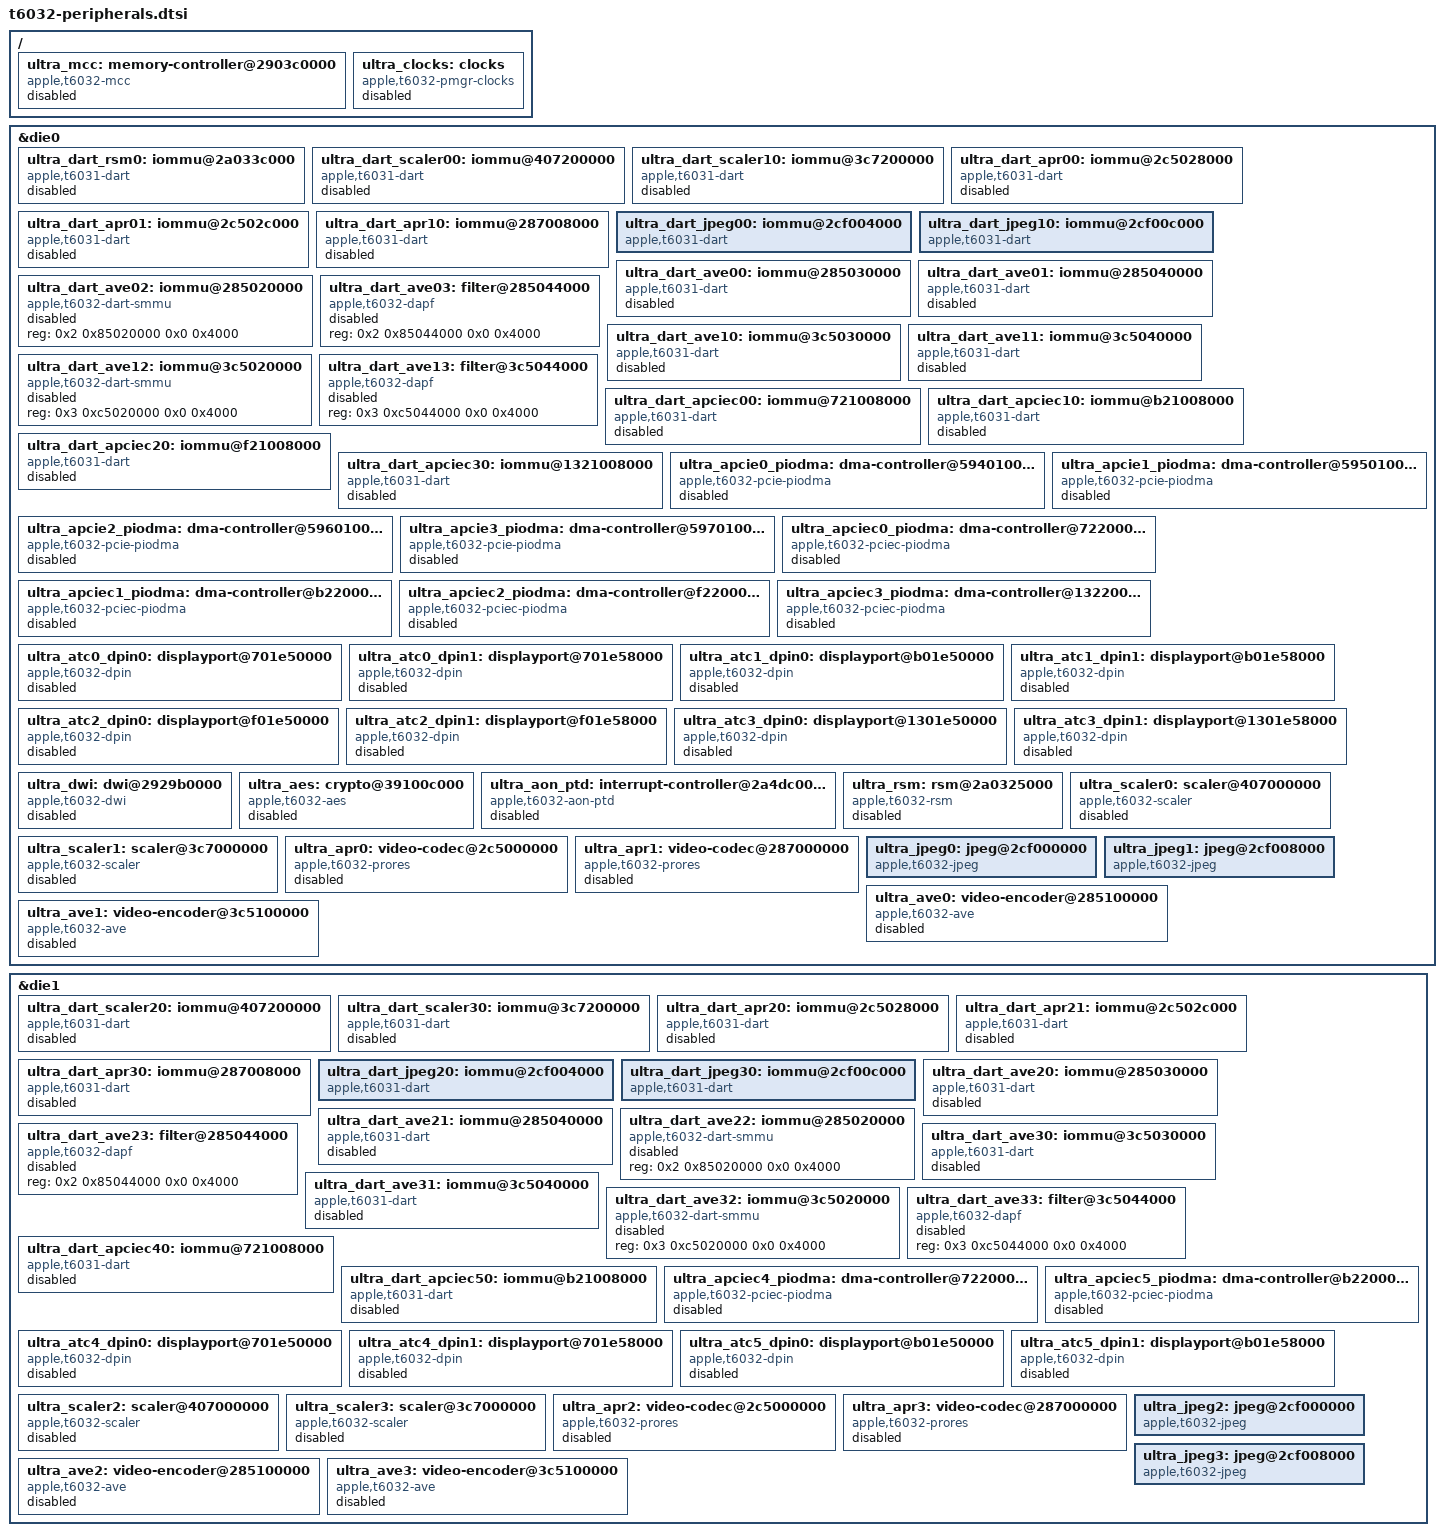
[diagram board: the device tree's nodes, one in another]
// SPDX-License-Identifier: GPL-2.0+ OR MIT
/* Unclaimed resources of both T6032 dies. */

&die0 {
	ultra_dart_rsm0: iommu@2a033c000 {
		compatible = "apple,t6031-dart", "apple,t8110-dart";
		reg = <0x2 0xa033c000 0x0 0x4000>;
		interrupt-parent = <&aic>;
		interrupts = <AIC_IRQ 0 559 IRQ_TYPE_LEVEL_HIGH>;
		#iommu-cells = <1>;
		status = "disabled";
	};

	ultra_dart_scaler00: iommu@407200000 {
		compatible = "apple,t6031-dart", "apple,t8110-dart";
		reg = <0x4 0x07200000 0x0 0x4000>;
		interrupt-parent = <&aic>;
		interrupts = <AIC_IRQ 0 1292 IRQ_TYPE_LEVEL_HIGH>;
		#iommu-cells = <1>;
		status = "disabled";
	};

	ultra_dart_scaler10: iommu@3c7200000 {
		compatible = "apple,t6031-dart", "apple,t8110-dart";
		reg = <0x3 0xc7200000 0x0 0x4000>;
		interrupt-parent = <&aic>;
		interrupts = <AIC_IRQ 0 1298 IRQ_TYPE_LEVEL_HIGH>;
		#iommu-cells = <1>;
		status = "disabled";
	};

	ultra_dart_apr00: iommu@2c5028000 {
		compatible = "apple,t6031-dart", "apple,t8110-dart";
		reg = <0x2 0xc5028000 0x0 0x4000>;
		interrupt-parent = <&aic>;
		interrupts = <AIC_IRQ 0 1737 IRQ_TYPE_LEVEL_HIGH>;
		#iommu-cells = <1>;
		status = "disabled";
	};

	ultra_dart_apr01: iommu@2c502c000 {
		compatible = "apple,t6031-dart", "apple,t8110-dart";
		reg = <0x2 0xc502c000 0x0 0x4000>;
		interrupt-parent = <&aic>;
		interrupts = <AIC_IRQ 0 1737 IRQ_TYPE_LEVEL_HIGH>;
		#iommu-cells = <1>;
		status = "disabled";
	};

	ultra_dart_apr10: iommu@287008000 {
		compatible = "apple,t6031-dart", "apple,t8110-dart";
		reg = <0x2 0x87008000 0x0 0x4000>;
		interrupt-parent = <&aic>;
		interrupts = <AIC_IRQ 0 1782 IRQ_TYPE_LEVEL_HIGH>;
		#iommu-cells = <1>;
		status = "disabled";
	};

	ultra_dart_jpeg00: iommu@2cf004000 {
		compatible = "apple,t6031-dart", "apple,t8110-dart";
		reg = <0x2 0xcf004000 0x0 0x4000>;
		interrupt-parent = <&aic>;
		interrupts = <AIC_IRQ 0 1283 IRQ_TYPE_LEVEL_HIGH>;
		#iommu-cells = <1>;
		status = "okay";
	};

	ultra_dart_jpeg10: iommu@2cf00c000 {
		compatible = "apple,t6031-dart", "apple,t8110-dart";
		reg = <0x2 0xcf00c000 0x0 0x4000>;
		interrupt-parent = <&aic>;
		interrupts = <AIC_IRQ 0 1288 IRQ_TYPE_LEVEL_HIGH>;
		#iommu-cells = <1>;
		status = "okay";
	};

	ultra_dart_ave00: iommu@285030000 {
		compatible = "apple,t6031-dart", "apple,t8110-dart";
		reg = <0x2 0x85030000 0x0 0x4000>;
		interrupt-parent = <&aic>;
		interrupts = <AIC_IRQ 0 1204 IRQ_TYPE_LEVEL_HIGH>;
		#iommu-cells = <1>;
		status = "disabled";
	};

	ultra_dart_ave01: iommu@285040000 {
		compatible = "apple,t6031-dart", "apple,t8110-dart";
		reg = <0x2 0x85040000 0x0 0x4000>;
		interrupt-parent = <&aic>;
		interrupts = <AIC_IRQ 0 1204 IRQ_TYPE_LEVEL_HIGH>;
		#iommu-cells = <1>;
		status = "disabled";
	};

	ultra_dart_ave02: iommu@285020000 {
		compatible = "apple,t6032-dart-smmu", "apple,dart-smmu";
		reg = <0x2 0x85020000 0x0 0x4000>;
		status = "disabled";
	};

	ultra_dart_ave03: filter@285044000 {
		compatible = "apple,t6032-dapf", "apple,dapf";
		reg = <0x2 0x85044000 0x0 0x4000>;
		status = "disabled";
	};

	ultra_dart_ave10: iommu@3c5030000 {
		compatible = "apple,t6031-dart", "apple,t8110-dart";
		reg = <0x3 0xc5030000 0x0 0x4000>;
		interrupt-parent = <&aic>;
		interrupts = <AIC_IRQ 0 1216 IRQ_TYPE_LEVEL_HIGH>;
		#iommu-cells = <1>;
		status = "disabled";
	};

	ultra_dart_ave11: iommu@3c5040000 {
		compatible = "apple,t6031-dart", "apple,t8110-dart";
		reg = <0x3 0xc5040000 0x0 0x4000>;
		interrupt-parent = <&aic>;
		interrupts = <AIC_IRQ 0 1216 IRQ_TYPE_LEVEL_HIGH>;
		#iommu-cells = <1>;
		status = "disabled";
	};

	ultra_dart_ave12: iommu@3c5020000 {
		compatible = "apple,t6032-dart-smmu", "apple,dart-smmu";
		reg = <0x3 0xc5020000 0x0 0x4000>;
		status = "disabled";
	};

	ultra_dart_ave13: filter@3c5044000 {
		compatible = "apple,t6032-dapf", "apple,dapf";
		reg = <0x3 0xc5044000 0x0 0x4000>;
		status = "disabled";
	};

	ultra_dart_apciec00: iommu@721008000 {
		compatible = "apple,t6031-dart", "apple,t8110-dart";
		reg = <0x7 0x21008000 0x0 0x4000>;
		interrupt-parent = <&aic>;
		interrupts = <AIC_IRQ 0 1348 IRQ_TYPE_LEVEL_HIGH>;
		#iommu-cells = <1>;
		status = "disabled";
	};

	ultra_dart_apciec10: iommu@b21008000 {
		compatible = "apple,t6031-dart", "apple,t8110-dart";
		reg = <0xb 0x21008000 0x0 0x4000>;
		interrupt-parent = <&aic>;
		interrupts = <AIC_IRQ 0 1376 IRQ_TYPE_LEVEL_HIGH>;
		#iommu-cells = <1>;
		status = "disabled";
	};

	ultra_dart_apciec20: iommu@f21008000 {
		compatible = "apple,t6031-dart", "apple,t8110-dart";
		reg = <0xf 0x21008000 0x0 0x4000>;
		interrupt-parent = <&aic>;
		interrupts = <AIC_IRQ 0 1404 IRQ_TYPE_LEVEL_HIGH>;
		#iommu-cells = <1>;
		status = "disabled";
	};

	ultra_dart_apciec30: iommu@1321008000 {
		compatible = "apple,t6031-dart", "apple,t8110-dart";
		reg = <0x13 0x21008000 0x0 0x4000>;
		interrupt-parent = <&aic>;
		interrupts = <AIC_IRQ 0 1432 IRQ_TYPE_LEVEL_HIGH>;
		#iommu-cells = <1>;
		status = "disabled";
	};

	ultra_apcie0_piodma: dma-controller@594010000 {
		compatible = "apple,t6032-pcie-piodma", "apple,pcie-piodma";
		reg = <0x5 0x94010000 0x0 0x4000>,
		      <0x5 0x94014000 0x0 0x4000>,
		      <0x5 0x94018000 0x0 0x4000>;
		interrupt-parent = <&aic>;
		interrupts = <AIC_IRQ 0 1493 IRQ_TYPE_LEVEL_HIGH>;
		iommus = <&pcie0_dart_0 15>;
		status = "disabled";
	};

	ultra_apcie1_piodma: dma-controller@595010000 {
		compatible = "apple,t6032-pcie-piodma", "apple,pcie-piodma";
		reg = <0x5 0x95010000 0x0 0x4000>,
		      <0x5 0x95014000 0x0 0x4000>,
		      <0x5 0x95018000 0x0 0x4000>;
		interrupt-parent = <&aic>;
		interrupts = <AIC_IRQ 0 1502 IRQ_TYPE_LEVEL_HIGH>;
		iommus = <&pcie0_dart_1 15>;
		status = "disabled";
	};

	ultra_apcie2_piodma: dma-controller@596010000 {
		compatible = "apple,t6032-pcie-piodma", "apple,pcie-piodma";
		reg = <0x5 0x96010000 0x0 0x4000>,
		      <0x5 0x96014000 0x0 0x4000>,
		      <0x5 0x96018000 0x0 0x4000>;
		interrupt-parent = <&aic>;
		interrupts = <AIC_IRQ 0 1511 IRQ_TYPE_LEVEL_HIGH>;
		status = "disabled";
	};

	ultra_apcie3_piodma: dma-controller@597010000 {
		compatible = "apple,t6032-pcie-piodma", "apple,pcie-piodma";
		reg = <0x5 0x97010000 0x0 0x4000>,
		      <0x5 0x97014000 0x0 0x4000>,
		      <0x5 0x97018000 0x0 0x4000>;
		interrupt-parent = <&aic>;
		interrupts = <AIC_IRQ 0 1520 IRQ_TYPE_LEVEL_HIGH>;
		status = "disabled";
	};

	ultra_apciec0_piodma: dma-controller@722000000 {
		compatible = "apple,t6032-pciec-piodma", "apple,pciec-piodma";
		reg = <0x7 0x22000000 0x0 0x4000>,
		      <0x7 0x22004000 0x0 0x4000>,
		      <0x7 0x22008000 0x0 0x4000>,
		      <0x7 0x20008000 0x0 0x4000>;
		interrupt-parent = <&aic>;
		interrupts = <AIC_IRQ 0 1349 IRQ_TYPE_LEVEL_HIGH>;
		iommus = <&ultra_dart_apciec00 15>;
		status = "disabled";
	};

	ultra_apciec1_piodma: dma-controller@b22000000 {
		compatible = "apple,t6032-pciec-piodma", "apple,pciec-piodma";
		reg = <0xb 0x22000000 0x0 0x4000>,
		      <0xb 0x22004000 0x0 0x4000>,
		      <0xb 0x22008000 0x0 0x4000>,
		      <0xb 0x20008000 0x0 0x4000>;
		interrupt-parent = <&aic>;
		interrupts = <AIC_IRQ 0 1377 IRQ_TYPE_LEVEL_HIGH>;
		iommus = <&ultra_dart_apciec10 15>;
		status = "disabled";
	};

	ultra_apciec2_piodma: dma-controller@f22000000 {
		compatible = "apple,t6032-pciec-piodma", "apple,pciec-piodma";
		reg = <0xf 0x22000000 0x0 0x4000>,
		      <0xf 0x22004000 0x0 0x4000>,
		      <0xf 0x22008000 0x0 0x4000>,
		      <0xf 0x20008000 0x0 0x4000>;
		interrupt-parent = <&aic>;
		interrupts = <AIC_IRQ 0 1405 IRQ_TYPE_LEVEL_HIGH>;
		iommus = <&ultra_dart_apciec20 15>;
		status = "disabled";
	};

	ultra_apciec3_piodma: dma-controller@1322000000 {
		compatible = "apple,t6032-pciec-piodma", "apple,pciec-piodma";
		reg = <0x13 0x22000000 0x0 0x4000>,
		      <0x13 0x22004000 0x0 0x4000>,
		      <0x13 0x22008000 0x0 0x4000>,
		      <0x13 0x20008000 0x0 0x4000>;
		interrupt-parent = <&aic>;
		interrupts = <AIC_IRQ 0 1433 IRQ_TYPE_LEVEL_HIGH>;
		iommus = <&ultra_dart_apciec30 15>;
		status = "disabled";
	};

	ultra_atc0_dpin0: displayport@701e50000 {
		compatible = "apple,t6032-dpin", "apple,dpin";
		reg = <0x7 0x01e50000 0x0 0x4000>;
		interrupt-parent = <&aic>;
		interrupts = <AIC_IRQ 0 1564 IRQ_TYPE_LEVEL_HIGH>;
		status = "disabled";
	};

	ultra_atc0_dpin1: displayport@701e58000 {
		compatible = "apple,t6032-dpin", "apple,dpin";
		reg = <0x7 0x01e58000 0x0 0x4000>;
		interrupt-parent = <&aic>;
		interrupts = <AIC_IRQ 0 1565 IRQ_TYPE_LEVEL_HIGH>;
		status = "disabled";
	};

	ultra_atc1_dpin0: displayport@b01e50000 {
		compatible = "apple,t6032-dpin", "apple,dpin";
		reg = <0xb 0x01e50000 0x0 0x4000>;
		interrupt-parent = <&aic>;
		interrupts = <AIC_IRQ 0 1612 IRQ_TYPE_LEVEL_HIGH>;
		status = "disabled";
	};

	ultra_atc1_dpin1: displayport@b01e58000 {
		compatible = "apple,t6032-dpin", "apple,dpin";
		reg = <0xb 0x01e58000 0x0 0x4000>;
		interrupt-parent = <&aic>;
		interrupts = <AIC_IRQ 0 1613 IRQ_TYPE_LEVEL_HIGH>;
		status = "disabled";
	};

	ultra_atc2_dpin0: displayport@f01e50000 {
		compatible = "apple,t6032-dpin", "apple,dpin";
		reg = <0xf 0x01e50000 0x0 0x4000>;
		interrupt-parent = <&aic>;
		interrupts = <AIC_IRQ 0 1660 IRQ_TYPE_LEVEL_HIGH>;
		status = "disabled";
	};

	ultra_atc2_dpin1: displayport@f01e58000 {
		compatible = "apple,t6032-dpin", "apple,dpin";
		reg = <0xf 0x01e58000 0x0 0x4000>;
		interrupt-parent = <&aic>;
		interrupts = <AIC_IRQ 0 1661 IRQ_TYPE_LEVEL_HIGH>;
		status = "disabled";
	};

	ultra_atc3_dpin0: displayport@1301e50000 {
		compatible = "apple,t6032-dpin", "apple,dpin";
		reg = <0x13 0x01e50000 0x0 0x4000>;
		interrupt-parent = <&aic>;
		interrupts = <AIC_IRQ 0 1708 IRQ_TYPE_LEVEL_HIGH>;
		status = "disabled";
	};

	ultra_atc3_dpin1: displayport@1301e58000 {
		compatible = "apple,t6032-dpin", "apple,dpin";
		reg = <0x13 0x01e58000 0x0 0x4000>;
		interrupt-parent = <&aic>;
		interrupts = <AIC_IRQ 0 1709 IRQ_TYPE_LEVEL_HIGH>;
		status = "disabled";
	};

	ultra_dwi: dwi@2929b0000 {
		compatible = "apple,t6032-dwi", "apple,dwi";
		reg = <0x2 0x929b0000 0x0 0x4000>;
		interrupt-parent = <&aic>;
		interrupts = <AIC_IRQ 0 22 IRQ_TYPE_LEVEL_HIGH>;
		power-domains = <&ps_dwi>;
		status = "disabled";
	};

	ultra_aes: crypto@39100c000 {
		compatible = "apple,t6032-aes", "apple,aes";
		reg = <0x3 0x9100c000 0x0 0x4000>,
		      <0x2 0xa02a0000 0x0 0x8000>;
		interrupt-parent = <&aic>;
		interrupts = <AIC_IRQ 0 1324 IRQ_TYPE_LEVEL_HIGH>;
		power-domains = <&ps_aes>;
		iommus = <&sio_dart 1>;
		status = "disabled";
	};

	ultra_aon_ptd: interrupt-controller@2a4dc0000 {
		compatible = "apple,t6032-aon-ptd", "apple,aon-ptd";
		reg = <0x2 0xa4dc0000 0x0 0x4000>,
		      <0x2 0xa4dd0000 0x0 0x4000>,
		      <0x2 0xa4dd8000 0x0 0x4000>,
		      <0x2 0xa4de0000 0x0 0x4000>;
		interrupt-parent = <&aic>;
		interrupts = <AIC_IRQ 0 920 IRQ_TYPE_LEVEL_HIGH>,
		             <AIC_IRQ 0 921 IRQ_TYPE_LEVEL_HIGH>,
		             <AIC_IRQ 0 922 IRQ_TYPE_LEVEL_HIGH>,
		             <AIC_IRQ 0 923 IRQ_TYPE_LEVEL_HIGH>,
		             <AIC_IRQ 0 924 IRQ_TYPE_LEVEL_HIGH>,
		             <AIC_IRQ 0 925 IRQ_TYPE_LEVEL_HIGH>,
		             <AIC_IRQ 0 926 IRQ_TYPE_LEVEL_HIGH>,
		             <AIC_IRQ 0 927 IRQ_TYPE_LEVEL_HIGH>,
		             <AIC_IRQ 0 928 IRQ_TYPE_LEVEL_HIGH>,
		             <AIC_IRQ 0 929 IRQ_TYPE_LEVEL_HIGH>,
		             <AIC_IRQ 0 930 IRQ_TYPE_LEVEL_HIGH>,
		             <AIC_IRQ 0 931 IRQ_TYPE_LEVEL_HIGH>,
		             <AIC_IRQ 0 932 IRQ_TYPE_LEVEL_HIGH>,
		             <AIC_IRQ 0 933 IRQ_TYPE_LEVEL_HIGH>,
		             <AIC_IRQ 0 934 IRQ_TYPE_LEVEL_HIGH>,
		             <AIC_IRQ 0 935 IRQ_TYPE_LEVEL_HIGH>,
		             <AIC_IRQ 0 936 IRQ_TYPE_LEVEL_HIGH>,
		             <AIC_IRQ 0 937 IRQ_TYPE_LEVEL_HIGH>,
		             <AIC_IRQ 0 938 IRQ_TYPE_LEVEL_HIGH>,
		             <AIC_IRQ 0 939 IRQ_TYPE_LEVEL_HIGH>,
		             <AIC_IRQ 0 940 IRQ_TYPE_LEVEL_HIGH>,
		             <AIC_IRQ 0 941 IRQ_TYPE_LEVEL_HIGH>,
		             <AIC_IRQ 0 942 IRQ_TYPE_LEVEL_HIGH>,
		             <AIC_IRQ 0 943 IRQ_TYPE_LEVEL_HIGH>,
		             <AIC_IRQ 0 944 IRQ_TYPE_LEVEL_HIGH>,
		             <AIC_IRQ 0 945 IRQ_TYPE_LEVEL_HIGH>,
		             <AIC_IRQ 0 946 IRQ_TYPE_LEVEL_HIGH>,
		             <AIC_IRQ 0 947 IRQ_TYPE_LEVEL_HIGH>,
		             <AIC_IRQ 0 948 IRQ_TYPE_LEVEL_HIGH>,
		             <AIC_IRQ 0 949 IRQ_TYPE_LEVEL_HIGH>,
		             <AIC_IRQ 0 950 IRQ_TYPE_LEVEL_HIGH>,
		             <AIC_IRQ 0 951 IRQ_TYPE_LEVEL_HIGH>;
		interrupt-controller;
		#interrupt-cells = <1>;
		#address-cells = <0>;
		status = "disabled";
	};

	ultra_rsm: rsm@2a0325000 {
		compatible = "apple,t6032-rsm", "apple,rsm";
		reg = <0x2 0xa0325000 0x0 0x4000>,
		      <0x2 0xa03c0000 0x0 0x4>;
		interrupt-parent = <&aic>;
		interrupts = <AIC_IRQ 0 556 IRQ_TYPE_LEVEL_HIGH>;
		power-domains = <&ps_debug_gated>;
		iommus = <&ultra_dart_rsm0 0>;
		status = "disabled";
	};

	ultra_scaler0: scaler@407000000 {
		compatible = "apple,t6032-scaler", "apple,scaler";
		reg = <0x4 0x07000000 0x0 0x30000>,
		      <0x4 0x07210000 0x0 0x4000>,
		      <0x4 0x07204000 0x0 0x4000>,
		      <0x4 0x06000000 0x0 0x8000>;
		interrupt-parent = <&aic>;
		interrupts = <AIC_IRQ 0 1291 IRQ_TYPE_LEVEL_HIGH>,
		             <AIC_IRQ 0 1293 IRQ_TYPE_LEVEL_HIGH>;
		power-domains = <&ps_msr0>, <&ps_msr0_ase_core>;
		iommus = <&ultra_dart_scaler00 0>, <&ultra_dart_scaler00 1>;
		clocks = <&ultra_clocks 414>;
		status = "disabled";
	};

	ultra_scaler1: scaler@3c7000000 {
		compatible = "apple,t6032-scaler", "apple,scaler";
		reg = <0x3 0xc7000000 0x0 0x30000>,
		      <0x3 0xc7210000 0x0 0x4000>,
		      <0x3 0xc7204000 0x0 0x4000>,
		      <0x3 0xc6000000 0x0 0x8000>;
		interrupt-parent = <&aic>;
		interrupts = <AIC_IRQ 0 1297 IRQ_TYPE_LEVEL_HIGH>,
		             <AIC_IRQ 0 1299 IRQ_TYPE_LEVEL_HIGH>;
		power-domains = <&ps_msr1>, <&ps_msr1_ase_core>;
		iommus = <&ultra_dart_scaler10 0>, <&ultra_dart_scaler10 1>;
		clocks = <&ultra_clocks 415>;
		status = "disabled";
	};

	ultra_apr0: video-codec@2c5000000 {
		compatible = "apple,t6032-prores", "apple,prores";
		reg = <0x2 0xc5000000 0x0 0x4000>,
		      <0x2 0xc4000000 0x0 0x1000000>,
		      <0x2 0xc5078000 0x0 0x4000>;
		interrupt-parent = <&aic>;
		interrupts = <AIC_IRQ 0 1738 IRQ_TYPE_LEVEL_HIGH>;
		power-domains = <&ps_scodec>;
		iommus = <&ultra_dart_apr00 1>, <&ultra_dart_apr01 1>;
		status = "disabled";
	};

	ultra_apr1: video-codec@287000000 {
		compatible = "apple,t6032-prores", "apple,prores";
		reg = <0x2 0x87000000 0x0 0x4000>,
		      <0x2 0x86000000 0x0 0x1000000>;
		interrupt-parent = <&aic>;
		interrupts = <AIC_IRQ 0 1785 IRQ_TYPE_LEVEL_HIGH>;
		power-domains = <&ps_prores>;
		iommus = <&ultra_dart_apr10 0>;
		status = "disabled";
	};

	ultra_jpeg0: jpeg@2cf000000 {
		compatible = "apple,t6032-jpeg", "apple,jpeg";
		reg = <0x2 0xcf000000 0x0 0x8000>;
		interrupt-parent = <&aic>;
		interrupts = <AIC_IRQ 0 1282 IRQ_TYPE_LEVEL_HIGH>;
		power-domains = <&ps_jpg>;
		iommus = <&ultra_dart_jpeg00 0>;
		clocks = <&ultra_clocks 350>, <&ultra_clocks 351>;
		status = "okay";
	};

	ultra_jpeg1: jpeg@2cf008000 {
		compatible = "apple,t6032-jpeg", "apple,jpeg";
		reg = <0x2 0xcf008000 0x0 0x8000>;
		interrupt-parent = <&aic>;
		interrupts = <AIC_IRQ 0 1287 IRQ_TYPE_LEVEL_HIGH>;
		power-domains = <&ps_jpg>;
		iommus = <&ultra_dart_jpeg10 0>;
		clocks = <&ultra_clocks 350>, <&ultra_clocks 351>;
		status = "okay";
	};

	ultra_ave0: video-encoder@285100000 {
		compatible = "apple,t6032-ave", "apple,ave";
		reg = <0x2 0x85100000 0x0 0x45c000>,
		      <0x2 0x85800000 0x0 0x800000>,
		      <0x2 0x85050000 0x0 0x4000>,
		      <0x2 0x92800430 0x0 0x20c>,
		      <0x2 0x84000000 0x0 0x1000000>;
		interrupt-parent = <&aic>;
		interrupts = <AIC_IRQ 0 1207 IRQ_TYPE_LEVEL_HIGH>,
		             <AIC_IRQ 0 1201 IRQ_TYPE_LEVEL_HIGH>,
		             <AIC_IRQ 0 1200 IRQ_TYPE_LEVEL_HIGH>,
		             <AIC_IRQ 0 1203 IRQ_TYPE_LEVEL_HIGH>,
		             <AIC_IRQ 0 1202 IRQ_TYPE_LEVEL_HIGH>;
		power-domains = <&ps_venc0_sys>, <&ps_venc0_pipe4>, <&ps_venc0_pipe5>, <&ps_venc0_me0>, <&ps_venc0_me1>, <&ps_venc0_dma>;
		iommus = <&ultra_dart_ave00 0>, <&ultra_dart_ave01 0>;
		status = "disabled";
	};

	ultra_ave1: video-encoder@3c5100000 {
		compatible = "apple,t6032-ave", "apple,ave";
		reg = <0x3 0xc5100000 0x0 0x45c000>,
		      <0x3 0xc5800000 0x0 0x800000>,
		      <0x3 0xc5050000 0x0 0x4000>,
		      <0x2 0x92280510 0x0 0x7b14>,
		      <0x3 0xc4000000 0x0 0x1000000>;
		interrupt-parent = <&aic>;
		interrupts = <AIC_IRQ 0 1219 IRQ_TYPE_LEVEL_HIGH>,
		             <AIC_IRQ 0 1213 IRQ_TYPE_LEVEL_HIGH>,
		             <AIC_IRQ 0 1212 IRQ_TYPE_LEVEL_HIGH>,
		             <AIC_IRQ 0 1215 IRQ_TYPE_LEVEL_HIGH>,
		             <AIC_IRQ 0 1214 IRQ_TYPE_LEVEL_HIGH>;
		power-domains = <&ps_venc1_pipe4>, <&ps_venc1_pipe5>, <&ps_venc1_me0>, <&ps_venc1_me1>, <&ps_venc1_dma>;
		iommus = <&ultra_dart_ave10 0>, <&ultra_dart_ave11 0>;
		status = "disabled";
	};

};

&die1 {
	ultra_dart_scaler20: iommu@407200000 {
		compatible = "apple,t6031-dart", "apple,t8110-dart";
		reg = <0x4 0x07200000 0x0 0x4000>;
		interrupt-parent = <&aic>;
		interrupts = <AIC_IRQ 1 1292 IRQ_TYPE_LEVEL_HIGH>;
		#iommu-cells = <1>;
		status = "disabled";
	};

	ultra_dart_scaler30: iommu@3c7200000 {
		compatible = "apple,t6031-dart", "apple,t8110-dart";
		reg = <0x3 0xc7200000 0x0 0x4000>;
		interrupt-parent = <&aic>;
		interrupts = <AIC_IRQ 1 1298 IRQ_TYPE_LEVEL_HIGH>;
		#iommu-cells = <1>;
		status = "disabled";
	};

	ultra_dart_apr20: iommu@2c5028000 {
		compatible = "apple,t6031-dart", "apple,t8110-dart";
		reg = <0x2 0xc5028000 0x0 0x4000>;
		interrupt-parent = <&aic>;
		interrupts = <AIC_IRQ 1 1737 IRQ_TYPE_LEVEL_HIGH>;
		#iommu-cells = <1>;
		status = "disabled";
	};

	ultra_dart_apr21: iommu@2c502c000 {
		compatible = "apple,t6031-dart", "apple,t8110-dart";
		reg = <0x2 0xc502c000 0x0 0x4000>;
		interrupt-parent = <&aic>;
		interrupts = <AIC_IRQ 1 1737 IRQ_TYPE_LEVEL_HIGH>;
		#iommu-cells = <1>;
		status = "disabled";
	};

	ultra_dart_apr30: iommu@287008000 {
		compatible = "apple,t6031-dart", "apple,t8110-dart";
		reg = <0x2 0x87008000 0x0 0x4000>;
		interrupt-parent = <&aic>;
		interrupts = <AIC_IRQ 1 1782 IRQ_TYPE_LEVEL_HIGH>;
		#iommu-cells = <1>;
		status = "disabled";
	};

	ultra_dart_jpeg20: iommu@2cf004000 {
		compatible = "apple,t6031-dart", "apple,t8110-dart";
		reg = <0x2 0xcf004000 0x0 0x4000>;
		interrupt-parent = <&aic>;
		interrupts = <AIC_IRQ 1 1283 IRQ_TYPE_LEVEL_HIGH>;
		#iommu-cells = <1>;
		status = "okay";
	};

	ultra_dart_jpeg30: iommu@2cf00c000 {
		compatible = "apple,t6031-dart", "apple,t8110-dart";
		reg = <0x2 0xcf00c000 0x0 0x4000>;
		interrupt-parent = <&aic>;
		interrupts = <AIC_IRQ 1 1288 IRQ_TYPE_LEVEL_HIGH>;
		#iommu-cells = <1>;
		status = "okay";
	};

	ultra_dart_ave20: iommu@285030000 {
		compatible = "apple,t6031-dart", "apple,t8110-dart";
		reg = <0x2 0x85030000 0x0 0x4000>;
		interrupt-parent = <&aic>;
		interrupts = <AIC_IRQ 1 1204 IRQ_TYPE_LEVEL_HIGH>;
		#iommu-cells = <1>;
		status = "disabled";
	};

	ultra_dart_ave21: iommu@285040000 {
		compatible = "apple,t6031-dart", "apple,t8110-dart";
		reg = <0x2 0x85040000 0x0 0x4000>;
		interrupt-parent = <&aic>;
		interrupts = <AIC_IRQ 1 1204 IRQ_TYPE_LEVEL_HIGH>;
		#iommu-cells = <1>;
		status = "disabled";
	};

	ultra_dart_ave22: iommu@285020000 {
		compatible = "apple,t6032-dart-smmu", "apple,dart-smmu";
		reg = <0x2 0x85020000 0x0 0x4000>;
		status = "disabled";
	};

	ultra_dart_ave23: filter@285044000 {
		compatible = "apple,t6032-dapf", "apple,dapf";
		reg = <0x2 0x85044000 0x0 0x4000>;
		status = "disabled";
	};

	ultra_dart_ave30: iommu@3c5030000 {
		compatible = "apple,t6031-dart", "apple,t8110-dart";
		reg = <0x3 0xc5030000 0x0 0x4000>;
		interrupt-parent = <&aic>;
		interrupts = <AIC_IRQ 1 1216 IRQ_TYPE_LEVEL_HIGH>;
		#iommu-cells = <1>;
		status = "disabled";
	};

	ultra_dart_ave31: iommu@3c5040000 {
		compatible = "apple,t6031-dart", "apple,t8110-dart";
		reg = <0x3 0xc5040000 0x0 0x4000>;
		interrupt-parent = <&aic>;
		interrupts = <AIC_IRQ 1 1216 IRQ_TYPE_LEVEL_HIGH>;
		#iommu-cells = <1>;
		status = "disabled";
	};

	ultra_dart_ave32: iommu@3c5020000 {
		compatible = "apple,t6032-dart-smmu", "apple,dart-smmu";
		reg = <0x3 0xc5020000 0x0 0x4000>;
		status = "disabled";
	};

	ultra_dart_ave33: filter@3c5044000 {
		compatible = "apple,t6032-dapf", "apple,dapf";
		reg = <0x3 0xc5044000 0x0 0x4000>;
		status = "disabled";
	};

	ultra_dart_apciec40: iommu@721008000 {
		compatible = "apple,t6031-dart", "apple,t8110-dart";
		reg = <0x7 0x21008000 0x0 0x4000>;
		interrupt-parent = <&aic>;
		interrupts = <AIC_IRQ 1 1348 IRQ_TYPE_LEVEL_HIGH>;
		#iommu-cells = <1>;
		status = "disabled";
	};

	ultra_dart_apciec50: iommu@b21008000 {
		compatible = "apple,t6031-dart", "apple,t8110-dart";
		reg = <0xb 0x21008000 0x0 0x4000>;
		interrupt-parent = <&aic>;
		interrupts = <AIC_IRQ 1 1376 IRQ_TYPE_LEVEL_HIGH>;
		#iommu-cells = <1>;
		status = "disabled";
	};

	ultra_apciec4_piodma: dma-controller@722000000 {
		compatible = "apple,t6032-pciec-piodma", "apple,pciec-piodma";
		reg = <0x7 0x22000000 0x0 0x4000>,
		      <0x7 0x22004000 0x0 0x4000>,
		      <0x7 0x22008000 0x0 0x4000>,
		      <0x7 0x20008000 0x0 0x4000>;
		interrupt-parent = <&aic>;
		interrupts = <AIC_IRQ 1 1349 IRQ_TYPE_LEVEL_HIGH>;
		iommus = <&ultra_dart_apciec40 15>;
		status = "disabled";
	};

	ultra_apciec5_piodma: dma-controller@b22000000 {
		compatible = "apple,t6032-pciec-piodma", "apple,pciec-piodma";
		reg = <0xb 0x22000000 0x0 0x4000>,
		      <0xb 0x22004000 0x0 0x4000>,
		      <0xb 0x22008000 0x0 0x4000>,
		      <0xb 0x20008000 0x0 0x4000>;
		interrupt-parent = <&aic>;
		interrupts = <AIC_IRQ 1 1377 IRQ_TYPE_LEVEL_HIGH>;
		iommus = <&ultra_dart_apciec50 15>;
		status = "disabled";
	};

	ultra_atc4_dpin0: displayport@701e50000 {
		compatible = "apple,t6032-dpin", "apple,dpin";
		reg = <0x7 0x01e50000 0x0 0x4000>;
		interrupt-parent = <&aic>;
		interrupts = <AIC_IRQ 1 1564 IRQ_TYPE_LEVEL_HIGH>;
		status = "disabled";
	};

	ultra_atc4_dpin1: displayport@701e58000 {
		compatible = "apple,t6032-dpin", "apple,dpin";
		reg = <0x7 0x01e58000 0x0 0x4000>;
		interrupt-parent = <&aic>;
		interrupts = <AIC_IRQ 1 1565 IRQ_TYPE_LEVEL_HIGH>;
		status = "disabled";
	};

	ultra_atc5_dpin0: displayport@b01e50000 {
		compatible = "apple,t6032-dpin", "apple,dpin";
		reg = <0xb 0x01e50000 0x0 0x4000>;
		interrupt-parent = <&aic>;
		interrupts = <AIC_IRQ 1 1612 IRQ_TYPE_LEVEL_HIGH>;
		status = "disabled";
	};

	ultra_atc5_dpin1: displayport@b01e58000 {
		compatible = "apple,t6032-dpin", "apple,dpin";
		reg = <0xb 0x01e58000 0x0 0x4000>;
		interrupt-parent = <&aic>;
		interrupts = <AIC_IRQ 1 1613 IRQ_TYPE_LEVEL_HIGH>;
		status = "disabled";
	};

	ultra_scaler2: scaler@407000000 {
		compatible = "apple,t6032-scaler", "apple,scaler";
		reg = <0x4 0x07000000 0x0 0x30000>,
		      <0x4 0x07210000 0x0 0x4000>,
		      <0x4 0x07204000 0x0 0x4000>,
		      <0x4 0x06000000 0x0 0x8000>;
		interrupt-parent = <&aic>;
		interrupts = <AIC_IRQ 1 1291 IRQ_TYPE_LEVEL_HIGH>,
		             <AIC_IRQ 1 1293 IRQ_TYPE_LEVEL_HIGH>;
		power-domains = <&ps_msr0_die1>, <&ps_msr0_ase_core_die1>;
		iommus = <&ultra_dart_scaler20 0>, <&ultra_dart_scaler20 1>;
		clocks = <&ultra_clocks 268435870>;
		status = "disabled";
	};

	ultra_scaler3: scaler@3c7000000 {
		compatible = "apple,t6032-scaler", "apple,scaler";
		reg = <0x3 0xc7000000 0x0 0x30000>,
		      <0x3 0xc7210000 0x0 0x4000>,
		      <0x3 0xc7204000 0x0 0x4000>,
		      <0x3 0xc6000000 0x0 0x8000>;
		interrupt-parent = <&aic>;
		interrupts = <AIC_IRQ 1 1297 IRQ_TYPE_LEVEL_HIGH>,
		             <AIC_IRQ 1 1299 IRQ_TYPE_LEVEL_HIGH>;
		power-domains = <&ps_msr1_die1>, <&ps_msr1_ase_core_die1>;
		iommus = <&ultra_dart_scaler30 0>, <&ultra_dart_scaler30 1>;
		clocks = <&ultra_clocks 268435871>;
		status = "disabled";
	};

	ultra_apr2: video-codec@2c5000000 {
		compatible = "apple,t6032-prores", "apple,prores";
		reg = <0x2 0xc5000000 0x0 0x4000>,
		      <0x2 0xc4000000 0x0 0x1000000>,
		      <0x2 0xc5078000 0x0 0x4000>;
		interrupt-parent = <&aic>;
		interrupts = <AIC_IRQ 1 1738 IRQ_TYPE_LEVEL_HIGH>;
		power-domains = <&ps_scodec_die1>;
		iommus = <&ultra_dart_apr20 1>, <&ultra_dart_apr21 1>;
		status = "disabled";
	};

	ultra_apr3: video-codec@287000000 {
		compatible = "apple,t6032-prores", "apple,prores";
		reg = <0x2 0x87000000 0x0 0x4000>,
		      <0x2 0x86000000 0x0 0x1000000>;
		interrupt-parent = <&aic>;
		interrupts = <AIC_IRQ 1 1785 IRQ_TYPE_LEVEL_HIGH>;
		power-domains = <&ps_prores_die1>;
		iommus = <&ultra_dart_apr30 0>;
		status = "disabled";
	};

	ultra_jpeg2: jpeg@2cf000000 {
		compatible = "apple,t6032-jpeg", "apple,jpeg";
		reg = <0x2 0xcf000000 0x0 0x8000>;
		interrupt-parent = <&aic>;
		interrupts = <AIC_IRQ 1 1282 IRQ_TYPE_LEVEL_HIGH>;
		power-domains = <&ps_jpg_die1>;
		iommus = <&ultra_dart_jpeg20 0>;
		clocks = <&ultra_clocks 268435806>, <&ultra_clocks 268435807>;
		status = "okay";
	};

	ultra_jpeg3: jpeg@2cf008000 {
		compatible = "apple,t6032-jpeg", "apple,jpeg";
		reg = <0x2 0xcf008000 0x0 0x8000>;
		interrupt-parent = <&aic>;
		interrupts = <AIC_IRQ 1 1287 IRQ_TYPE_LEVEL_HIGH>;
		power-domains = <&ps_jpg_die1>;
		iommus = <&ultra_dart_jpeg30 0>;
		clocks = <&ultra_clocks 268435806>, <&ultra_clocks 268435807>;
		status = "okay";
	};

	ultra_ave2: video-encoder@285100000 {
		compatible = "apple,t6032-ave", "apple,ave";
		reg = <0x2 0x85100000 0x0 0x45c000>,
		      <0x2 0x85800000 0x0 0x800000>,
		      <0x2 0x85050000 0x0 0x4000>,
		      <0x2 0x92800430 0x0 0x20c>,
		      <0x2 0x84000000 0x0 0x1000000>;
		interrupt-parent = <&aic>;
		interrupts = <AIC_IRQ 1 1207 IRQ_TYPE_LEVEL_HIGH>,
		             <AIC_IRQ 1 1201 IRQ_TYPE_LEVEL_HIGH>,
		             <AIC_IRQ 1 1200 IRQ_TYPE_LEVEL_HIGH>,
		             <AIC_IRQ 1 1203 IRQ_TYPE_LEVEL_HIGH>,
		             <AIC_IRQ 1 1202 IRQ_TYPE_LEVEL_HIGH>;
		power-domains = <&ps_venc0_sys_die1>, <&ps_venc0_pipe4_die1>, <&ps_venc0_pipe5_die1>, <&ps_venc0_me0_die1>, <&ps_venc0_me1_die1>, <&ps_venc0_dma_die1>;
		iommus = <&ultra_dart_ave20 0>, <&ultra_dart_ave21 0>;
		status = "disabled";
	};

	ultra_ave3: video-encoder@3c5100000 {
		compatible = "apple,t6032-ave", "apple,ave";
		reg = <0x3 0xc5100000 0x0 0x45c000>,
		      <0x3 0xc5800000 0x0 0x800000>,
		      <0x3 0xc5050000 0x0 0x4000>,
		      <0x2 0x92280510 0x0 0x7b14>,
		      <0x3 0xc4000000 0x0 0x1000000>;
		interrupt-parent = <&aic>;
		interrupts = <AIC_IRQ 1 1219 IRQ_TYPE_LEVEL_HIGH>,
		             <AIC_IRQ 1 1213 IRQ_TYPE_LEVEL_HIGH>,
		             <AIC_IRQ 1 1212 IRQ_TYPE_LEVEL_HIGH>,
		             <AIC_IRQ 1 1215 IRQ_TYPE_LEVEL_HIGH>,
		             <AIC_IRQ 1 1214 IRQ_TYPE_LEVEL_HIGH>;
		power-domains = <&ps_venc1_pipe4_die1>, <&ps_venc1_pipe5_die1>, <&ps_venc1_me0_die1>, <&ps_venc1_me1_die1>, <&ps_venc1_dma_die1>;
		iommus = <&ultra_dart_ave30 0>, <&ultra_dart_ave31 0>;
		status = "disabled";
	};

};

/ {
	ultra_mcc: memory-controller@2903c0000 {
		compatible = "apple,t6032-mcc", "apple,mcc";
		reg = <0x2 0x903c0000 0x0 0x20000>,
		      <0x2 0x904d0000 0x0 0x149c>,
		      <0x2 0x92818000 0x0 0x4000>,
		      <0x22 0x92818000 0x0 0x4000>,
		      <0x2 0x20000000 0x0 0x2000000>,
		      <0x2 0x22000000 0x0 0x2000000>,
		      <0x2 0x24000000 0x0 0x2000000>,
		      <0x2 0x26000000 0x0 0x2000000>,
		      <0x2 0x28000000 0x0 0x2000000>,
		      <0x2 0x2a000000 0x0 0x2000000>,
		      <0x2 0x2c000000 0x0 0x2000000>,
		      <0x2 0x2e000000 0x0 0x2000000>,
		      <0x22 0x20000000 0x0 0x2000000>,
		      <0x22 0x22000000 0x0 0x2000000>,
		      <0x22 0x24000000 0x0 0x2000000>,
		      <0x22 0x26000000 0x0 0x2000000>,
		      <0x22 0x28000000 0x0 0x2000000>,
		      <0x22 0x2a000000 0x0 0x2000000>,
		      <0x22 0x2c000000 0x0 0x2000000>,
		      <0x22 0x2e000000 0x0 0x2000000>;
		status = "disabled";
	};

};

/ {
	ultra_clocks: clocks {
		compatible = "apple,t6032-pmgr-clocks", "apple,pmgr-clocks";
		#clock-cells = <1>;
		status = "disabled";
	};
};
